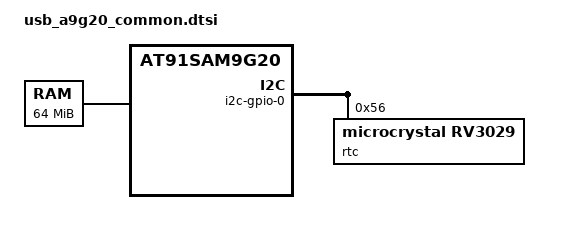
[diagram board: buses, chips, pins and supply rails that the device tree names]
// SPDX-License-Identifier: GPL-2.0-or-later
/*
 * usb_a9g20.dts - Device Tree file for Calao USB A9G20 board
 *
 *  Copyright (C) 2011 Jean-Christophe PLAGNIOL-VILLARD <plagnioj@jcrosoft.com>
 */

#include "at91sam9g20.dtsi"
#include "usb_a9260_common.dtsi"

/ {
	chosen {
		bootargs = "mem=64M root=/dev/mtdblock5 rw rootfstype=ubifs";
		stdout-path = "serial0:115200n8";
	};

	memory@20000000 {
		reg = <0x20000000 0x4000000>;
	};

	i2c-gpio-0 {
		rtc@56 {
			compatible = "microcrystal,rv3029";
			reg = <0x56>;
		};
	};
};
